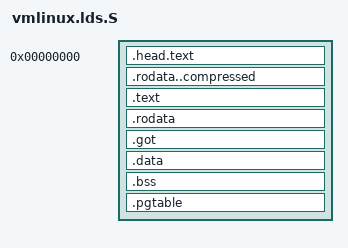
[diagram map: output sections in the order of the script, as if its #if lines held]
/* * Copyright (c) 2010 - 2012 Intel Corporation.
*
* Disclaimer: The codes contained in these modules may be specific to the
* Intel Software Development Platform codenamed: Knights Ferry, and the 
* Intel product codenamed: Knights Corner, and are not backward compatible 
* with other Intel products. Additionally, Intel will NOT support the codes 
* or instruction set in future products.
*
* Intel offers no warranty of any kind regarding the code.  This code is
* licensed on an "AS IS" basis and Intel is not obligated to provide any support,
* assistance, installation, training, or other services of any kind.  Intel is 
* also not obligated to provide any updates, enhancements or extensions.  Intel 
* specifically disclaims any warranty of merchantability, non-infringement, 
* fitness for any particular purpose, and any other warranty.
*
* Further, Intel disclaims all liability of any kind, including but not
* limited to liability for infringement of any proprietary rights, relating
* to the use of the code, even if Intel is notified of the possibility of
* such liability.  Except as expressly stated in an Intel license agreement
* provided with this code and agreed upon with Intel, no license, express
* or implied, by estoppel or otherwise, to any intellectual property rights
* is granted herein.
*/
#include <asm-generic/vmlinux.lds.h>

OUTPUT_FORMAT(CONFIG_OUTPUT_FORMAT, CONFIG_OUTPUT_FORMAT, CONFIG_OUTPUT_FORMAT)

#undef i386

#include <asm/cache.h>
#include <asm/page_types.h>

#ifdef CONFIG_X86_64
#if defined(CONFIG_ML1OM)
OUTPUT_ARCH(l1om)
#elif defined(CONFIG_MK1OM)
OUTPUT_ARCH(k1om)
#else
OUTPUT_ARCH(i386:x86-64)
#endif
ENTRY(startup_64)
#else
OUTPUT_ARCH(i386)
ENTRY(startup_32)
#endif

SECTIONS
{
	/* Be careful parts of head_64.S assume startup_32 is at
	 * address 0.
	 */
	. = 0;
	.head.text : {
		_head = . ;
		HEAD_TEXT
		_ehead = . ;
	}
	.rodata..compressed : {
		*(.rodata..compressed)
	}
	.text :	{
		_text = .; 	/* Text */
		*(.text)
		*(.text.*)
		_etext = . ;
	}
	.rodata : {
		_rodata = . ;
		*(.rodata)	 /* read-only data */
		*(.rodata.*)
		_erodata = . ;
	}
	.got : {
		_got = .;
		KEEP(*(.got.plt))
		KEEP(*(.got))
		_egot = .;
	}
	.data :	{
		_data = . ;
		*(.data)
		*(.data.*)
		_edata = . ;
	}
	. = ALIGN(L1_CACHE_BYTES);
	.bss : {
		_bss = . ;
		*(.bss)
		*(.bss.*)
		*(COMMON)
		. = ALIGN(8);	/* For convenience during zeroing */
		_ebss = .;
	}
#ifdef CONFIG_X86_64
       . = ALIGN(PAGE_SIZE);
       .pgtable : {
		_pgtable = . ;
		*(.pgtable)
		_epgtable = . ;
	}
#endif
	_end = .;
}
